# STM32F412Rx register map
File version: 1.0
Registers are 32-bit, read-write, reset 0x0 unless marked. A register's access mark holds for its fields unless they carry their own. Offsets are from the block's base; [hi:lo] are bit positions; lines under a group give offsets from that group; {n}, {i} and the like mark numbered series; 'fields as' and 'values as' point back to an identical list.

## DFSDM1
Base 0x40016000
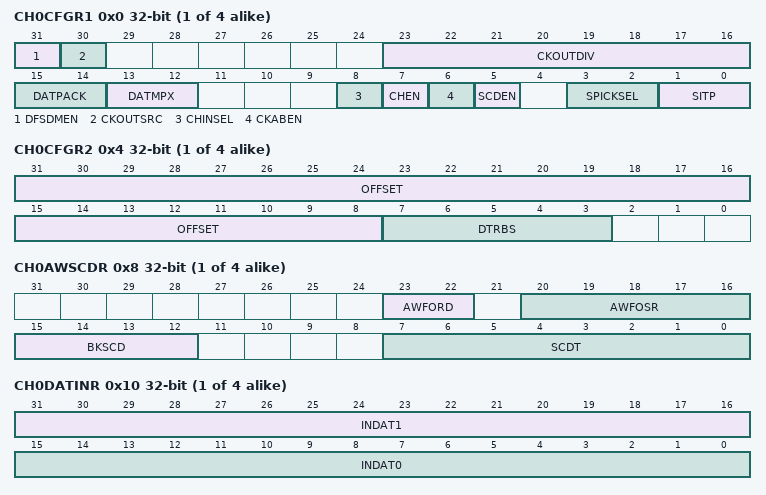
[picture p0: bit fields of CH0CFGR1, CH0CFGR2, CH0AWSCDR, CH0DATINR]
{0x0+0x20*i} CH{i}CFGR1 (i=0..3) — DFSDM channel configuration register1
  [31] DFSDMEN — Global enable for DFSDM interface
  [30] CKOUTSRC — Output serial clock source selection
  [23:16] CKOUTDIV — CKOUTDIV[7:0] output serial clock divider
  [15:14] DATPACK — DATPACK[1:0] Data packing mode
  [13:12] DATMPX — DATMPX[1:0] Input data multiplexer for channel y
  [8] CHINSEL — Serial inputs selection for channel y
  [7] CHEN — Channel y enable
  [6] CKABEN — Clock absence detector enable on channel y
  [5] SCDEN — Short circuit detector enable on channel y
  [3:2] SPICKSEL — SPICKSEL[1:0] SPI clock select for channel y
  [1:0] SITP — SITP[1:0] Serial interface type for channel y
{0x4+0x20*i} CH{i}CFGR2 (i=0..3) — DFSDM channel configuration register2
  [31:8] OFFSET — OFFSET[23:0] 24-bit calibration offset for channel y
  [7:3] DTRBS — DTRBS[4:0] Data right bit-shift for channel y
{0x8+0x20*i} CH{i}AWSCDR (i=0..3) — DFSDM channel analog watchdog and short circuit detector register
  [23:22] AWFORD — AWFORD[1:0] Analog watchdog Sinc filter order on channel y
  [20:16] AWFOSR — AWFOSR[4:0] Analog watchdog filter oversampling ratio on channel y
  [15:12] BKSCD — BKSCD[3:0] Break signal assignment for short circuit detector on channel y
  [7:0] SCDT — SCDT[7:0] Short circuit detector threshold for channel y
{0xC+0x20*i} CH{i}WDATAR (i=0..3) — DFSDM channel watchdog filter data register
{0x10+0x20*i} CH{i}DATINR (i=0..3) — DFSDM channel data input register
  [31:16] INDAT1 — INDAT0[15:0] Input data for channel y
  [15:0] INDAT0 — INDAT0[31:16] Input data for channel y or channel (y+1)
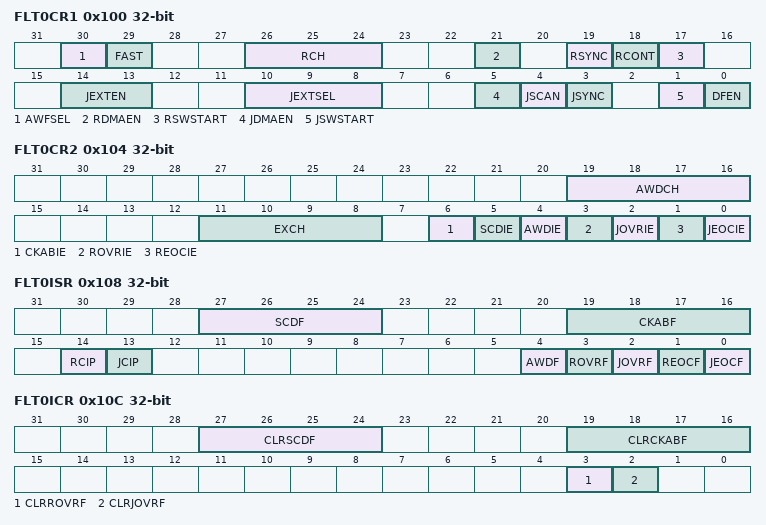
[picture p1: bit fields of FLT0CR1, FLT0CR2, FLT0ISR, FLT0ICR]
0x100 FLT0CR1 — DFSDM control register1
  [30] AWFSEL — Analog watchdog fast mode select
  [29] FAST — Fast conversion mode selection
  [26:24] RCH — RCH[2:0] Regular channel selection
  [21] RDMAEN — DMA channel enabled to read data for the regular conversion
  [19] RSYNC — Launch regular conversion synchronously with DFSDMx
  [18] RCONT — Continuous mode selection for regular conversions
  [17] RSWSTART — Software start of a conversion on the regular channel
  [14:13] JEXTEN — JEXTEN[1:0] Trigger enable and trigger edge selection for injected conversions
  [10:8] JEXTSEL — JEXTSEL[2:0]Trigger signal selection for launching injected conversions
  [5] JDMAEN — DMA channel enabled to read data for the injected channel group
  [4] JSCAN — Scanning conversion in continuous mode selection for injected conversions
  [3] JSYNC — Launch an injected conversion synchronously with DFSDMx JSWSTART trigger
  [1] JSWSTART — Start the conversion of the injected group of channels
  [0] DFEN — DFSDM enable
0x104 FLT0CR2 — DFSDM control register2
  [19:16] AWDCH — AWDCH[7:0] Analog watchdog channel selection
  [11:8] EXCH — EXCH[7:0] Extreme detector channel selection
  [6] CKABIE — Clock absence interrupt enable
  [5] SCDIE — Short circuit detector interrupt enable
  [4] AWDIE — Analog watchdog interrupt enable
  [3] ROVRIE — Regular data overrun interrupt enable
  [2] JOVRIE — Injected data overrun interrupt enable
  [1] REOCIE — Regular end of conversion interrupt enable
  [0] JEOCIE — Injected end of conversion interrupt enable
0x108 FLT0ISR — DFSDM interrupt and status register
  [27:24] SCDF — SCDF[7:0] Short circuit detector flag
  [19:16] CKABF — CKABF[7:0] Clock absence flag
  [14] RCIP — Regular conversion in progress status
  [13] JCIP — Injected conversion in progress status
  [4] AWDF — Analog watchdog
  [3] ROVRF — Regular conversion overrun flag
  [2] JOVRF — Injected conversion overrun flag
  [1] REOCF — End of regular conversion flag
  [0] JEOCF — End of injected conversion flag
0x10C FLT0ICR — DFSDM interrupt flag clear register
  [27:24] CLRSCDF — CLRSCSDF[7:0] Clear the short circuit detector flag
  [19:16] CLRCKABF — CLRCKABF[7:0] Clear the clock absence flag
  [3] CLRROVRF — Clear the regular conversion overrun flag
  [2] CLRJOVRF — Clear the injected conversion overrun flag
0x110 FLT0JCHGR — DFSDM injected channel group selection register
  [3:0] JCHG — JCHG[7:0] Injected channel group selection
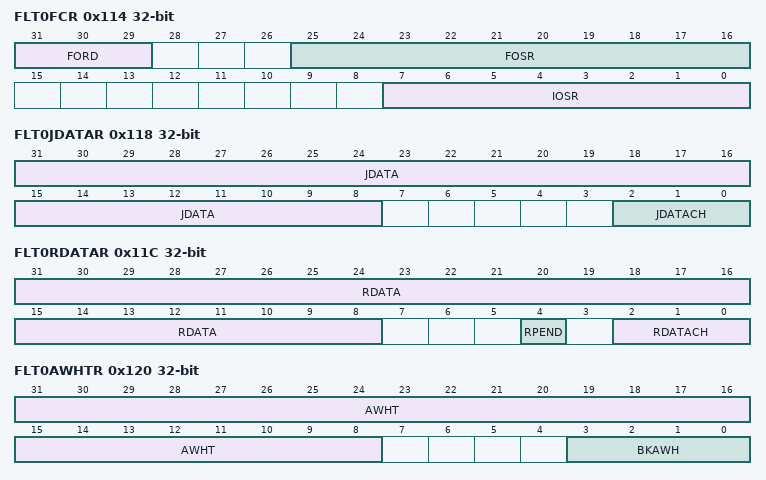
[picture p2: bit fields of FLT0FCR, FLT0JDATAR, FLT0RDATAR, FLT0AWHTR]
0x114 FLT0FCR — DFSDM filter control register
  [31:29] FORD — FORD[2:0] Sinc filter order
  [25:16] FOSR — FOSR[9:0] Sinc filter oversampling ratio (decimation rate)
  [7:0] IOSR — IOSR[7:0] Integrator oversampling ratio (averaging length)
0x118 FLT0JDATAR — DFSDM data register for injected group
  [31:8] JDATA — JDATA[23:0] Injected group conversion data
  [2:0] JDATACH — JDATACH[2:0] Injected channel most recently converted
0x11C FLT0RDATAR — DFSDM data register for regular group
  [31:8] RDATA — RDATA[23:0] Regular channel conversion data
  [4] RPEND — RPEND Regular channel pending data
  [2:0] RDATACH — RDATACH[2:0] Regular channel most recently converted
0x120 FLT0AWHTR — DFSDM analog watchdog high threshold register
  [31:8] AWHT — AWHT[23:0] Analog watchdog high threshold
  [3:0] BKAWH — BKAWH[3:0] Break signal assignment to analog watchdog high threshold event
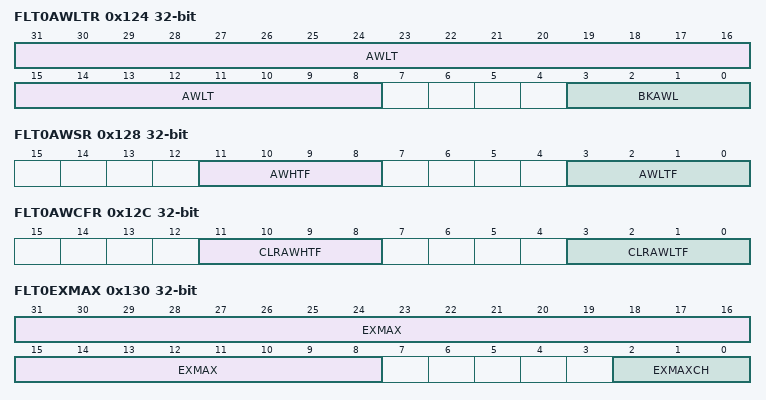
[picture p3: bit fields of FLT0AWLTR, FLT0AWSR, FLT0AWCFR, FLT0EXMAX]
0x124 FLT0AWLTR — DFSDM analog watchdog low threshold register
  [31:8] AWLT — AWLT[23:0] Analog watchdog low threshold
  [3:0] BKAWL — BKAWL[3:0] Break signal assignment to analog watchdog low threshold event
0x128 FLT0AWSR — DFSDM analog watchdog status register
  [11:8] AWHTF — AWHTF[15:8] Analog watchdog high threshold error on given channels
  [3:0] AWLTF — AWLTF[7:0] Analog watchdog low threshold error on given channels
0x12C FLT0AWCFR — DFSDM analog watchdog clear flag register
  [11:8] CLRAWHTF — CLRAWHTF[15:8] Clear the Analog watchdog high threshold flag
  [3:0] CLRAWLTF — CLRAWLTF[7:0] Clear the Analog watchdog low threshold flag
0x130 FLT0EXMAX — DFSDM extreme detector maximum register
  [31:8] EXMAX — EXMAX[23:0] Extreme detector maximum value
  [2:0] EXMAXCH — EXMAXCH[2:0] Extreme detector maximum data channel
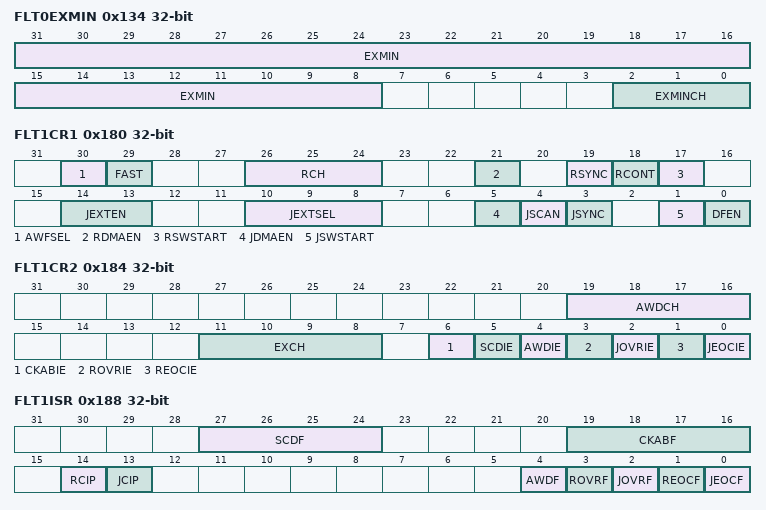
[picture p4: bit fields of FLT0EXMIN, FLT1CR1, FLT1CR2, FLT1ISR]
0x134 FLT0EXMIN — DFSDM extreme detector minimum register
  [31:8] EXMIN — EXMIN[23:0] Extreme detector minimum value
  [2:0] EXMINCH — EXMINCH[2:0] Extreme detector minimum data channel
0x138 FLT0CNVTIMR — DFSDM conversion timer
  [31:4] CNVCNT — CNVCNT[27:0]: 28-bit timer counting conversion time
0x180 FLT1CR1 — DFSDM control register1
  fields as FLT0CR1
0x184 FLT1CR2 — DFSDM control register2
  fields as FLT0CR2
0x188 FLT1ISR — DFSDM interrupt and status register
  fields as FLT0ISR
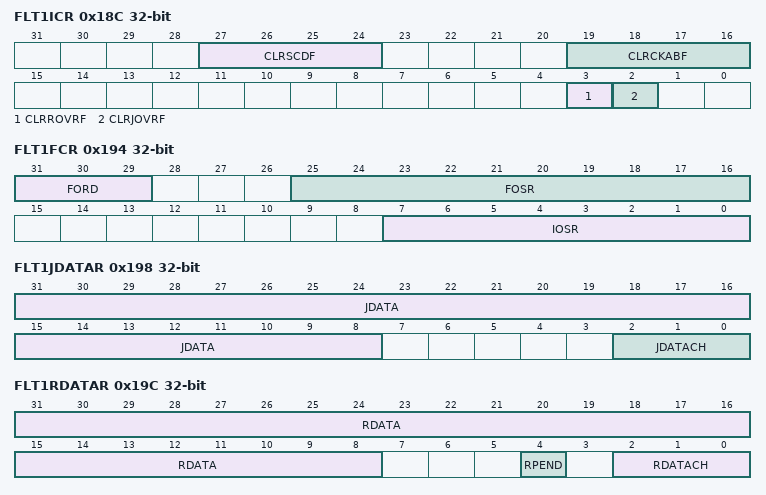
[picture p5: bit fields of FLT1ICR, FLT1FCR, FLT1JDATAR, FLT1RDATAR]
0x18C FLT1ICR — DFSDM interrupt flag clear register
  fields as FLT0ICR
0x190 FLT1JCHGR — DFSDM injected channel group selection register
  [3:0] JCHG — JCHG[7:0] Injected channel group selection
0x194 FLT1FCR — DFSDM filter control register
  fields as FLT0FCR
0x198 FLT1JDATAR — DFSDM data register for injected group
  fields as FLT0JDATAR
0x19C FLT1RDATAR — DFSDM data register for regular group
  fields as FLT0RDATAR
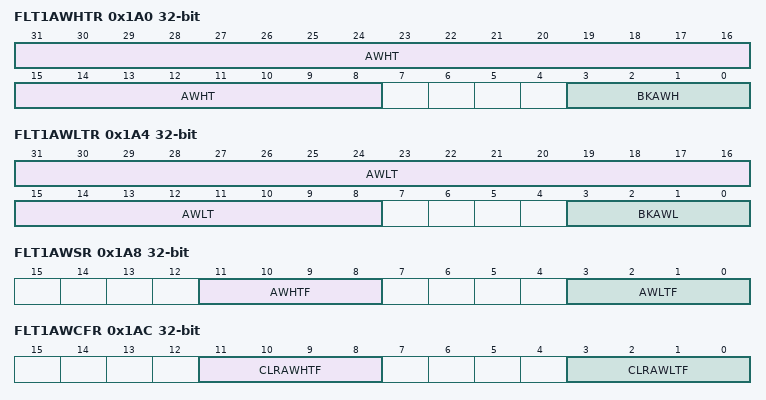
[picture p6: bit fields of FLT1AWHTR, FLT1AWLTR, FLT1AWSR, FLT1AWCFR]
0x1A0 FLT1AWHTR — DFSDM analog watchdog high threshold register
  fields as FLT0AWHTR
0x1A4 FLT1AWLTR — DFSDM analog watchdog low threshold register
  fields as FLT0AWLTR
0x1A8 FLT1AWSR — DFSDM analog watchdog status register
  fields as FLT0AWSR
0x1AC FLT1AWCFR — DFSDM analog watchdog clear flag register
  fields as FLT0AWCFR
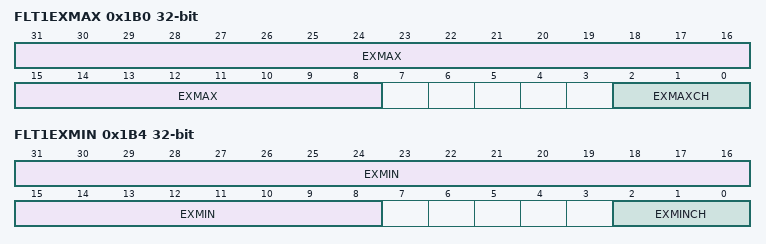
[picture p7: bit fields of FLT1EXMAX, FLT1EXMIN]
0x1B0 FLT1EXMAX — DFSDM extreme detector maximum register
  fields as FLT0EXMAX
0x1B4 FLT1EXMIN — DFSDM extreme detector minimum register
  fields as FLT0EXMIN
0x1B8 FLT1CNVTIMR — DFSDM conversion timer
  [31:4] CNVCNT — CNVCNT[27:0]: 28-bit timer counting conversion time
